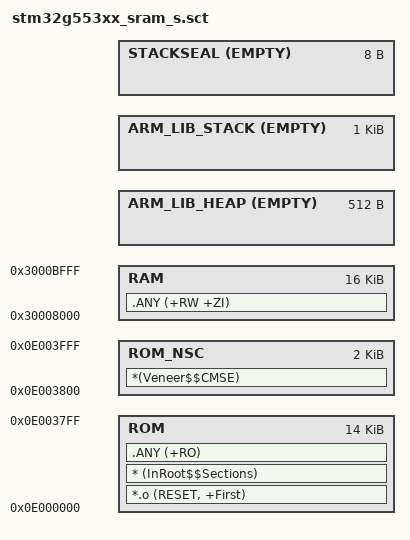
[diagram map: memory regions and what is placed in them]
#! armclang -E --target=arm-arm-none-eabi -mcpu=cortex-m33 -xc
; command above MUST be in first line (no comment above!)

; ******************************************************************************
; * @file    stm32g553xx_sram_s.sct
; * @brief   Linker File
; ******************************************************************************
; * @attention
; *
; * Copyright (c) 2026 STMicroelectronics.
; * All rights reserved.
; *
; * This software is licensed under terms that can be found in the LICENSE file
; * in the root directory of this software component.
; * If no LICENSE file comes with this software, it is provided AS-IS.
; *
; ******************************************************************************

#define __HEAP_SIZE 0x200
#define __STACK_SIZE 0x400
#define __STACKSEAL_SIZE 0x8


ROM 0xE000000 0x3800
{
  ROM 0xE000000 0x3800
  {
    *.o (RESET, +First)
    * (InRoot$$Sections)
    .ANY (+RO)
  }

  RAM 0x30008000 0x4000
  {
    .ANY (+RW +ZI)
  }

  ARM_LIB_HEAP AlignExpr(+0, 8) EMPTY  __HEAP_SIZE
  {
  }

  ARM_LIB_STACK AlignExpr(+0, 8) EMPTY  __STACK_SIZE
  {
  }

  STACKSEAL +0 EMPTY  __STACKSEAL_SIZE
  {
  }
}

ROM_NSC 0xE003800 0x800
{
  ROM_NSC 0xE003800 0x800
  {
    *(Veneer$$CMSE)
  }
}
